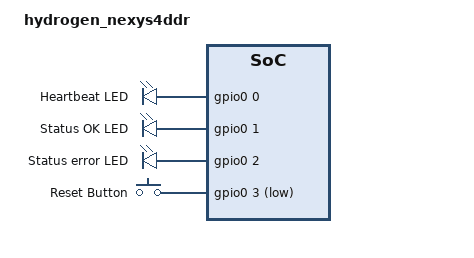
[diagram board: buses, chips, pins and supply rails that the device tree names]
/*
 * Copyright (c) 2021 Phytec Messtechnik GmbH
 *
 * SPDX-License-Identifier: Apache-2.0
 */

/dts-v1/;

#include <hydrogen3.dtsi>

/ {
	model = "hydrogen_nexys4ddr";
	compatible = "hydrogen,hydrogen_nexys4ddr";

	aliases {
		uart-0 = &uart0;
		gpio-0 = &gpio0;
	};

	chosen {
		zephyr,console = &uart0;
		zephyr,shell-uart = &uart0;
		zephyr,sram = &ram0;
	};

	leds {
		compatible = "gpio-leds";

		heartbeat: HEARTBEAT {
			gpios = <&gpio0 0 GPIO_ACTIVE_HIGH>;
			label = "Heartbeat LED";
		};

		ok: OK {
			gpios = <&gpio0 1 GPIO_ACTIVE_HIGH>;
			label = "Status OK LED";
		};

		error: ERROR {
			gpios = <&gpio0 2 GPIO_ACTIVE_HIGH>;
			label = "Status error LED";
		};
	};

	keys {
		compatible = "gpio-keys";

		reset: RESET {
			gpios = <&gpio0 3 GPIO_ACTIVE_LOW>;
			label = "Reset Button";
		};
	};
};
